# ATmega644 register map
Vendor: Atmel; File version: 1.0
CPU: other r0p0, little endian, no MPU, no FPU, 4 interrupt priority bits
Registers are 8-bit, read-write, reset 0x0 unless marked. A register's access mark holds for its fields unless they carry their own. Offsets are from the block's base; [hi:lo] are bit positions; {n}, {i} and the like mark numbered series.

## BOOT_LOAD — Bootloader
Base 0x00800057
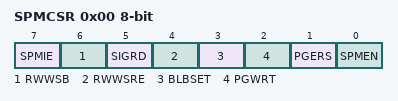
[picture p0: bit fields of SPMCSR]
0x00 SPMCSR — Store Program Memory Control Register
  [7] SPMIE — SPM Interrupt Enable
  [6] RWWSB — Read While Write Section Busy
  [5] SIGRD — Signature Row Read
  [4] RWWSRE — Read While Write section read enable
  [3] BLBSET — Boot Lock Bit Set
  [2] PGWRT — Page Write
  [1] PGERS — Page Erase
  [0] SPMEN — Store Program Memory Enable

## CPU — CPU Registers
Base 0x0080003E
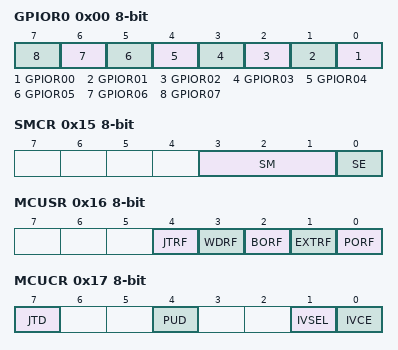
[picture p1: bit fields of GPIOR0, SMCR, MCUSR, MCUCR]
0x00 GPIOR0 — General Purpose IO Register 0
  [n] GPIOR{n:02} (n=0..7) — General Purpose IO Register 0 bit {n}
0x0C GPIOR1 — General Purpose IO Register 1
  [7:0] GPIOR — General Purpose IO Register 1 bis
0x0D GPIOR2 — General Purpose IO Register 2
  [7:0] GPIOR — General Purpose IO Register 2 bis
0x15 SMCR — Sleep Mode Control Register
  [3:1] SM — Sleep Mode Select bits
    0=IDLE; 1=ADC (ADC Noise Reduction (If Available)); 2=PDOWN (Power Down); 3=PSAVE (Power Save); 6=STDBY (Standby); 7=ESTDBY (Extended Standby)
  [0] SE — Sleep Enable
0x16 MCUSR — MCU Status Register
  [4] JTRF — JTAG Reset Flag
  [3] WDRF — Watchdog Reset Flag
  [2] BORF — Brown-out Reset Flag
  [1] EXTRF — External Reset Flag
  [0] PORF — Power-on reset flag
0x17 MCUCR — MCU Control Register
  [7] JTD — JTAG Interface Disable
  [4] PUD — Pull-up disable
  [1] IVSEL — Interrupt Vector Select
  [0] IVCE — Interrupt Vector Change Enable
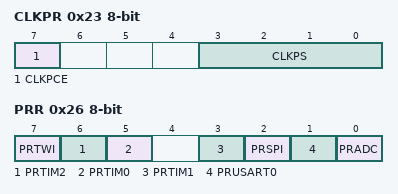
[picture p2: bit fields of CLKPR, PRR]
0x23 CLKPR
  [7] CLKPCE
  [3:0] CLKPS
    0=1; 1=2; 2=4; 3=8; 4=16; 5=32; 6=64; 7=128; 8=256
0x26 PRR — Power Reduction Register
  [7] PRTWI — Power Reduction TWI
  [6] PRTIM2 — Power Reduction Timer/Counter2
  [5] PRTIM0 — Power Reduction Timer/Counter0
  [3] PRTIM1 — Power Reduction Timer/Counter1
  [2] PRSPI — Power Reduction Serial Peripheral Interface
  [1] PRUSART0 — Power Reduction USART
  [0] PRADC — Power Reduction ADC
0x28 OSCCAL — Oscillator Calibration Value
  [7:0] OSCCAL — Oscillator Calibration

## EEPROM
Base 0x0080003F
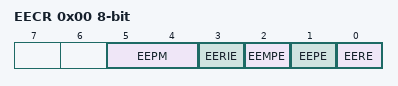
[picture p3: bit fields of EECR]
0x00 EECR — EEPROM Control Register
  [5:4] EEPM — EEPROM Programming Mode Bits
    0=ERASE_AND_WRITE_IN_ONE_OPERATION; 1=ERASE_ONLY; 2=WRITE_ONLY
  [3] EERIE — EEPROM Ready Interrupt Enable
  [2] EEMPE — EEPROM Master Write Enable
  [1] EEPE — EEPROM Write Enable
  [0] EERE — EEPROM Read Enable
0x01 EEDR — EEPROM Data Register
0x02 EEAR 16-bit (reset mask 0xFF) — EEPROM Address Register Low Bytes

## EXINT — External Interrupts
Base 0x0080003B
0x00 PCIFR — Pin Change Interrupt Flag Register (read-only for debugger)
  [3:0] PCIF — Pin Change Interrupt Flags
0x01 EIFR — External Interrupt Flag Register (read-only for debugger)
  [2:0] INTF — External Interrupt Flags
0x02 EIMSK — External Interrupt Mask Register
  [2:0] INT — External Interrupt Request 2 Enable
0x2D PCICR — Pin Change Interrupt Control Register
  [3:0] PCIE — Pin Change Interrupt Enables
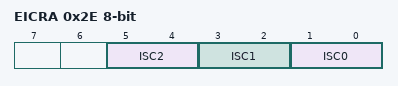
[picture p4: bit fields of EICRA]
0x2E EICRA — External Interrupt Control Register A
  [all] fields
    0=LOW_LEVEL_OF_INTX; 1=ANY_LOGICAL_CHANGE_OF_INTX; 2=FALLING_EDGE_OF_INTX; 3=RISING_EDGE_OF_INTX
  [5:4] ISC2 — External Interrupt Sense Control Bit
  [3:2] ISC1 — External Interrupt Sense Control Bit
  [1:0] ISC0 — External Interrupt Sense Control Bit
{0x30+i} PCMSK{i} (i=0..2) — Pin Change Mask Register {i}
  [7:0] PCINT — Pin Change Enable Masks
0x38 PCMSK3 — Pin Change Mask Register 3
  [7:0] PCINT — Pin Change Enable Masks

## JTAG — JTAG Interface
Base 0x00800051
0x00 OCDR — On-Chip Debug Related Register in I/O Memory (write-only for debugger)
0x03 MCUSR — MCU Status Register (read-only for debugger)
  [4] JTRF — JTAG Reset Flag
0x04 MCUCR — MCU Control Register
  [7] JTD — JTAG Interface Disable

## LOCKBIT — Lockbits
Base 0x00800000
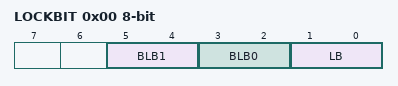
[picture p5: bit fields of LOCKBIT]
0x00 LOCKBIT
  [5:4] BLB1 — Boot Loader Protection Mode
    0=LPM_SPM_DISABLE (LPM and SPM prohibited in Boot Section); 1=LPM_DISABLE (LPM prohibited in Boot Section); 2=SPM_DISABLE (SPM prohibited in Boot Section); 3=NO_LOCK (No lock on SPM and LPM in Boot Section)
  [3:2] BLB0 — Boot Loader Protection Mode
    0=LPM_SPM_DISABLE (LPM and SPM prohibited in Application Section); 1=LPM_DISABLE (LPM prohibited in Application Section); 2=SPM_DISABLE (SPM prohibited in Application Section); 3=NO_LOCK (No lock on SPM and LPM in Application Section)
  [1:0] LB — Memory Lock
    0=PROG_VER_DISABLED (Further programming and verification disabled); 2=PROG_DISABLED (Further programming disabled); 3=NO_LOCK (No memory lock features enabled)
